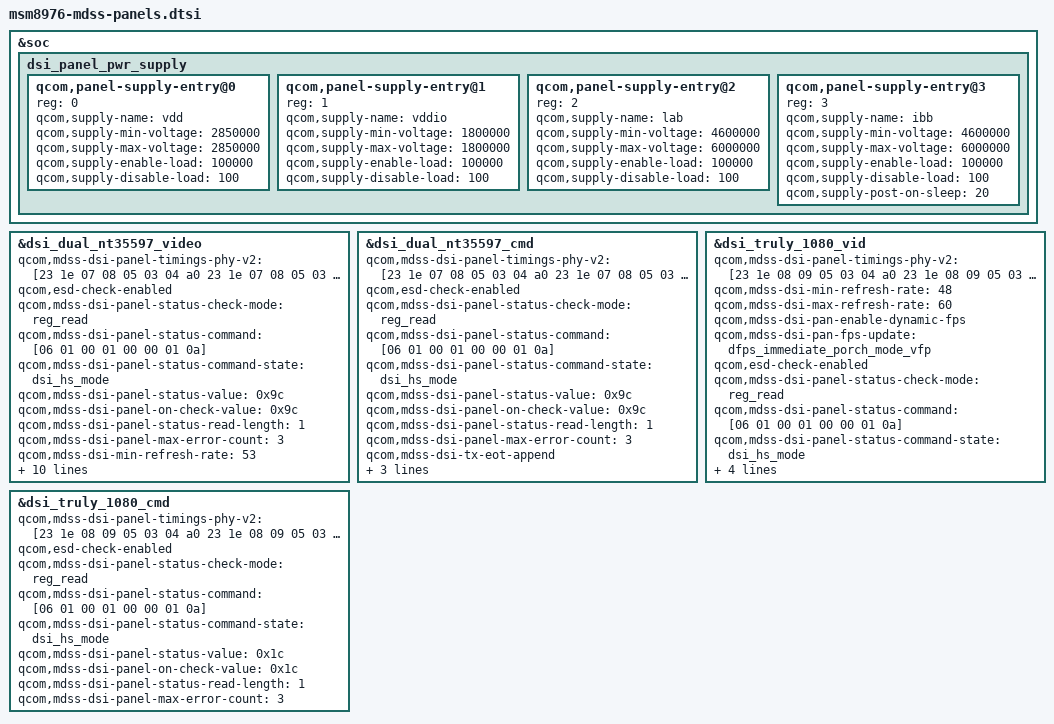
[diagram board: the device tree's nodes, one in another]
// SPDX-License-Identifier: GPL-2.0
// Copyright (c) 2015, The Linux Foundation. All rights reserved.
// Copyright (c) 2023-2024, Benarji Anand <benarji385@gmail.com>

#include "dsi-panel-sim-video.dtsi"
#include "dsi-panel-sim-cmd.dtsi"
#include "dsi-panel-nt35597-dualmipi-wqxga-video.dtsi"
#include "dsi-panel-nt35597-dualmipi-wqxga-cmd.dtsi"
#include "dsi-panel-otm1906c-1080p-cmd.dtsi"
#include "dsi-panel-hx8399a-1080p-video.dtsi"
#include "dsi-panel-nt35597-dsc-wqxga-video.dtsi"
#include "dsi-panel-nt35597-dsc-wqxga-cmd.dtsi"
#include "dsi-panel-truly-1080p-video.dtsi"
#include "dsi-panel-tianma-nt35596-1080p-video.dtsi"
#include "dsi-panel-boe-nt35532-1080p-video.dtsi"
#include "dsi-panel-sharp-r63315-1080p-video.dtsi"
#include "dsi-panel-truly-1080p-cmd.dtsi"
#include "dsi-panel-adv7533-1080p-video.dtsi"
#include "dsi-panel-adv7533-720p-video.dtsi"
#include "dsi-panel-nt35523-dualmipi-wqxga-video.dtsi"

&soc {
	dsi_panel_pwr_supply: dsi_panel_pwr_supply {
		#address-cells = <1>;
		#size-cells = <0>;

		qcom,panel-supply-entry@0 {
			reg = <0>;
			qcom,supply-name = "vdd";
			qcom,supply-min-voltage = <2850000>;
			qcom,supply-max-voltage = <2850000>;
			qcom,supply-enable-load = <100000>;
			qcom,supply-disable-load = <100>;
		};

		qcom,panel-supply-entry@1 {
			reg = <1>;
			qcom,supply-name = "vddio";
			qcom,supply-min-voltage = <1800000>;
			qcom,supply-max-voltage = <1800000>;
			qcom,supply-enable-load = <100000>;
			qcom,supply-disable-load = <100>;
		};

		qcom,panel-supply-entry@2 {
			reg = <2>;
			qcom,supply-name = "lab";
			qcom,supply-min-voltage = <4600000>;
			qcom,supply-max-voltage = <6000000>;
			qcom,supply-enable-load = <100000>;
			qcom,supply-disable-load = <100>;
		};

		qcom,panel-supply-entry@3 {
			reg = <3>;
			qcom,supply-name = "ibb";
			qcom,supply-min-voltage = <4600000>;
			qcom,supply-max-voltage = <6000000>;
			qcom,supply-enable-load = <100000>;
			qcom,supply-disable-load = <100>;
			qcom,supply-post-on-sleep = <20>;
		};
	};
};

&dsi_dual_nt35597_video {
	qcom,mdss-dsi-panel-timings-phy-v2 = [23 1e 07 08 05 03 04 a0
		23 1e 07 08 05 03 04 a0
		23 1e 07 08 05 03 04 a0
		23 1e 07 08 05 03 04 a0
		23 18 07 08 04 03 04 a0];
	qcom,esd-check-enabled;
	qcom,mdss-dsi-panel-status-check-mode = "reg_read";
	qcom,mdss-dsi-panel-status-command = [06 01 00 01 00 00 01 0a];
	qcom,mdss-dsi-panel-status-command-state = "dsi_hs_mode";
	qcom,mdss-dsi-panel-status-value = <0x9c>;
	qcom,mdss-dsi-panel-on-check-value = <0x9c>;
	qcom,mdss-dsi-panel-status-read-length = <1>;
	qcom,mdss-dsi-panel-max-error-count = <3>;
	qcom,mdss-dsi-min-refresh-rate = <53>;
	qcom,mdss-dsi-max-refresh-rate = <60>;
	qcom,mdss-dsi-pan-enable-dynamic-bitclk;
	qcom,mdss-dsi-dynamic-bitclk_freq = <798240576 801594528 804948480
		808302432 811656384>;
	qcom,mdss-dsi-pan-enable-dynamic-fps;
	qcom,mdss-dsi-pan-fps-update = "dfps_immediate_porch_mode_vfp";
	qcom,mdss-dsi-tx-eot-append;
	qcom,mdss-dsi-t-clk-post = <0x0d>;
	qcom,mdss-dsi-t-clk-pre = <0x2d>;
};

&dsi_dual_nt35597_cmd {
	qcom,mdss-dsi-panel-timings-phy-v2 = [23 1e 07 08 05 03 04 a0
		23 1e 07 08 05 03 04 a0
		23 1e 07 08 05 03 04 a0
		23 1e 07 08 05 03 04 a0
		23 18 07 08 04 03 04 a0];
	qcom,esd-check-enabled;
	qcom,mdss-dsi-panel-status-check-mode = "reg_read";
	qcom,mdss-dsi-panel-status-command = [06 01 00 01 00 00 01 0a];
	qcom,mdss-dsi-panel-status-command-state = "dsi_hs_mode";
	qcom,mdss-dsi-panel-status-value = <0x9c>;
	qcom,mdss-dsi-panel-on-check-value = <0x9c>;
	qcom,mdss-dsi-panel-status-read-length = <1>;
	qcom,mdss-dsi-panel-max-error-count = <3>;
	qcom,mdss-dsi-tx-eot-append;
	qcom,mdss-dsi-t-clk-post = <0x0d>;
	qcom,mdss-dsi-t-clk-pre = <0x2d>;
	qcom,ulps-enabled;
};

&dsi_truly_1080_vid {
	qcom,mdss-dsi-panel-timings-phy-v2 = [23 1e 08 09 05 03 04 a0
		23 1e 08 09 05 03 04 a0
		23 1e 08 09 05 03 04 a0
		23 1e 08 09 05 03 04 a0
		23 1a 08 09 05 03 04 a0];
	qcom,mdss-dsi-min-refresh-rate = <48>;
	qcom,mdss-dsi-max-refresh-rate = <60>;
	qcom,mdss-dsi-pan-enable-dynamic-fps;
	qcom,mdss-dsi-pan-fps-update = "dfps_immediate_porch_mode_vfp";
	qcom,esd-check-enabled;
	qcom,mdss-dsi-panel-status-check-mode = "reg_read";
	qcom,mdss-dsi-panel-status-command = [06 01 00 01 00 00 01 0a];
	qcom,mdss-dsi-panel-status-command-state = "dsi_hs_mode";
	qcom,mdss-dsi-panel-status-value = <0x1c>;
	qcom,mdss-dsi-panel-on-check-value = <0x1c>;
	qcom,mdss-dsi-panel-status-read-length = <1>;
	qcom,mdss-dsi-panel-max-error-count = <3>;
};

&dsi_truly_1080_cmd {
	qcom,mdss-dsi-panel-timings-phy-v2 = [23 1e 08 09 05 03 04 a0
		23 1e 08 09 05 03 04 a0
		23 1e 08 09 05 03 04 a0
		23 1e 08 09 05 03 04 a0
		23 1a 08 09 05 03 04 a0];
	qcom,esd-check-enabled;
	qcom,mdss-dsi-panel-status-check-mode = "reg_read";
	qcom,mdss-dsi-panel-status-command = [06 01 00 01 00 00 01 0a];
	qcom,mdss-dsi-panel-status-command-state = "dsi_hs_mode";
	qcom,mdss-dsi-panel-status-value = <0x1c>;
	qcom,mdss-dsi-panel-on-check-value = <0x1c>;
	qcom,mdss-dsi-panel-status-read-length = <1>;
	qcom,mdss-dsi-panel-max-error-count = <3>;
};
